# MDR1986VE8 register map
Vendor: Milandr; Series: ARMCM4; File version: 2.0
ARM 32-bit Cortex-M4 Microcontroller based device, CPU clock up to 60MHz, etc.
CPU: CM4 r0p0, little endian, MPU, FPU, 3 interrupt priority bits
Registers are 32-bit, read-write, reset 0x0 unless marked. A register's access mark holds for its fields unless they carry their own. Offsets are from the block's base; lines under a group give offsets from that group; [hi:lo] are bit positions; {n}, {i} and the like mark numbered series; 'fields as' and 'values as' point back to an identical list; <NAME> marks a mode.

## Memory map
0x21000000 MDR_ETH1 size 0x3A — Ethernet Control
0x40000000 MDR_RST_CLOCK size 0x1D0 — CLock Control
0x40001000 MDR_BKP size 0x184 — Backup and RTC Control
0x40006000 MDR_OTP size 0x28 — OTP Memory Control
0x40080000 MDR_PORTA size 0x8C — PORTA
0x40081000 MDR_PORTB size 0x8C — PORTB
0x40082000 MDR_PORTC size 0x8C — PORTC
0x40083000 MDR_PORTD size 0x8C — PORTD
0x40084000 MDR_PORTE size 0x8C — PORTE
0x4008A000 MDR_TIMER1 size 0x90 — TIMER Control
0x4008B000 MDR_TIMER2 size 0x90
0x4008C000 MDR_TIMER3 size 0x90
0x4008D000 MDR_TIMER4 size 0x90
0x40090000 MDR_CAN1 size 0x600 — CAN Control
0x40095000 MDR_SSP1 size 0x28 — Synchronous Serial Port
0x40099000 MDR_UART1 size 0x84 — UART Control
0x4009A000 MDR_UART2 size 0x84
0xE0042000 MDR_DMA size 0x70 — DMA Controler

## MDR_OTP — OTP Memory Control
Base 0x40006000
0x00 KEY — Unlock block register
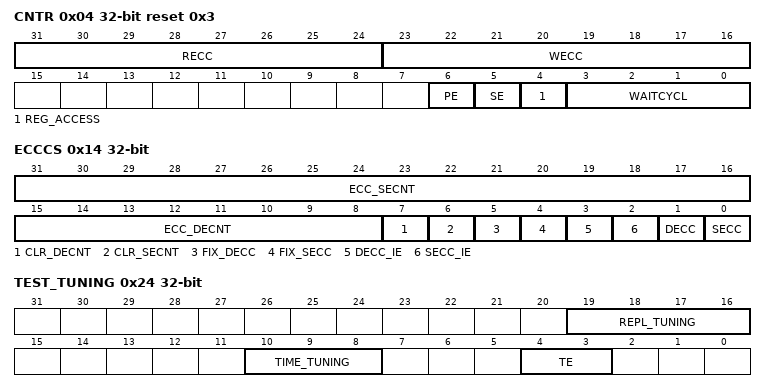
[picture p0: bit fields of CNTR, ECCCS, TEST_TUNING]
0x04 CNTR reset 0x3 — Control register
  [31:24] RECC — ECC after read with RDATA
  [23:16] WECC — ECC for write with WDATA
  [6] PE — OTP Programming enable
    0=Off (Hold data); 1=On (Programming enable)
  [5] SE — OTP Read enable
    0=Off (Hold data); 1=On (Read enable)
  [4] REG_ACCESS — OTP Access Delay
    0=Off (Bus access); 1=On (Access through registers)
  [3:0] WAITCYCL — OTP Access Delay
    0=Forbiden value; 1=20MHz83 (Delay for clock up to 20.83 MHz); 2=41MHz66 (Delay for clock up to 41.66 MHz); 3=62MHz5 (Delay for clock up to 62.5 MHz); 4=83MHz33 (Delay for clock up to 83.33 MHz); 5=100MHz (Delay for clock up to 100 MHz)
0x08 ADR — Access address
0x0C WDATA — Data to write
0x10 RDATA — Read out data
0x14 ECCCS — Control-Status Register
  [31:16] ECC_SECNT — SE Events Counter
  [15:8] ECC_DECNT — DE Events Counter
  [7] CLR_DECNT — Clear DE counter
    0=Inactive (No Action); 1=Clear (Action)
  [6] CLR_SECNT — Clear SE counter
    0=Inactive (No Action); 1=Clear (Action)
  [5] FIX_DECC — Log DE to ECCADR, ECCDATA, ECCECC
    0=Off (Disable); 1=On (Enable)
  [4] FIX_SECC — Log SE to ECCADR, ECCDATA, ECCECC
    0=Off (Disable); 1=On (Enable)
  [3] DECC_IE — DoubleError IRQ Enable
    0=Off (Disable); 1=On (Enable)
  [2] SECC_IE — SingleError IRQ Enable
    0=Off (Disable); 1=On (Enable)
  [1] DECC — DoubleError flag
    0=Off (No Event detected); 1=On (Event detected)
  [0] SECC — SingleError flag
    0=Off (No Event detected); 1=On (Event detected)
0x18 ECCADR — Last error address without correction
0x1C ECCDATA — Last error data without correction
0x20 ECCECC (reset mask 0xFF) — Last error ECC without correction
0x24 TEST_TUNING — Access Memory Tuning register
  [19:16] REPL_TUNING — Bit Hi_Level Read Resistance
    0=Repl_EasyMax (Read Resistance); 1=Repl_Easy1 (Read Resistance); 2=Repl_Norm (Read Resistance); {v}=Repl_Hard{v-2} (Read Resistance) (v=3..14); 15=Repl_HardMax (Read Resistance)
  [10:8] TIME_TUNING — Timeouts to read bit
    0=Time_HardMax (Read Timeout); 1=Time_Hard2 (Read Timeout); 2=Time_Hard1 (Read Timeout); 3=Time_Norm (Read Timeout); 4=Time_Easy1 (Read Timeout); 5=Time_Easy2 (Read Timeout); 6=Time_Easy3 (Read Timeout); 7=Time_EasyMax (Read Timeout)
  [4:3] TE — Select Test Mode
    0=Off (Normal Operation); 1=Test_1 (Test Mode 1); 2=Test_2 (Test Mode 2); 3=Test_3 (Test Mode 3)

## MDR_SSP1 — Synchronous Serial Port
Base 0x40095000
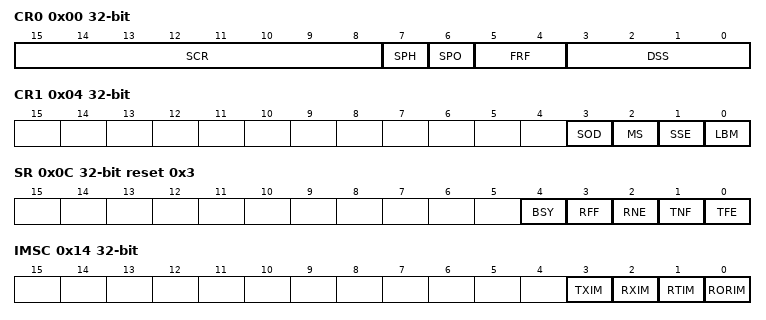
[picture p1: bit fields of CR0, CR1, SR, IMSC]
0x00 CR0 — Control Register 0
  [15:8] SCR — Signal CLock Rate
  [7] SPH — SPI Capture Clock Phase
    0=Leading (Capture data on leading edge); 1=Trailing (Capture data on trailing edge)
  [6] SPO — SPI Clock Polarity
    0=Idle_Low (Idle state is Low); 1=Idle_High (Idle state is High)
  [5:4] FRF — Frame Format
    0=SPI (Motorola SPI protocol); 1=SSI (Texas Instruments SSI protocol); 2=Microwire (National Semiconductor Microwire protocol)
  [3:0] DSS — Data Size Select
    {v}=bits_{v+1} (Word of {v+1} bits) (v=3..15)
0x04 CR1 — Control Register 1
  [3] SOD — Slave mode Output Disable
    0=SlaveTxEna (Slave mode transmit enable); 1=SlaveTxDis (Slave mode transmit disable)
  [2] MS — Master or Slave mode
    0=Master Mode; 1=Slave Mode
  [1] SSE — Synchronous Serial Enable
    0=Off (SSP Disable); 1=On (SSP Enable)
  [0] LBM — Loop Back Mode
    0=Normal operation; 1=LoopBack (TX send to RX test mode)
0x08 DR — FIFO_Rx and FIFO_Tx access
  [15:0] Data — Data value
0x0C SR ro reset 0x3 — Status Register
  [4] BSY — Transfer in progress
    0=Idle (FIFO_RX is Not Full); 1=Busy (Transfering)
  [3] RFF — FIFO_RX is Full
    0=RX_NotFull (FIFO_RX is Not Full); 1=RX_Full (FIFO_RX is Full)
  [2] RNE — FIFO_RX is Not Empty
    0=RX_NotEmpty (FIFO_RX is Empty); 1=RX_Empty (FIFO_RX is Not Empty)
  [1] TNF — FIFO_TX is Not Full
    0=TX_Full (FIFO_TX is Full); 1=TX_NotFull (FIFO_TX is Not Full)
  [0] TFE — FIFO_TX is Empty
    0=TX_NotEmpty (FIFO_TX is Not Empty); 1=TX_Empty (FIFO_TX is Empty)
0x10 CPSR — Clock Prescaller Register
  [7:0] CPSDVSR — Clock Prescaller
0x14 IMSC — IRQ Mask Set-Clear
  [3] TXIM — Enable IQR on FIFO_TX le 4 words
    0=NoEvent (Flag Inactive); 1=TX_HalfEmpty (Flag Active)
  [2] RXIM — Enable IQR on FIFO_RX ge 4 words
    0=NoEvent (Flag Inactive); 1=RX_HalfFull (Flag Active)
  [1] RTIM — Enable IQR on RX timeout for 32bits
    0=NoEvent (Flag Inactive); 1=RX_Timeout (Flag Active)
  [0] RORIM — Enable IRQ on FIFO_RX overrun
    0=NoEvent (Flag Inactive); 1=RX_Overrun (Flag Active)
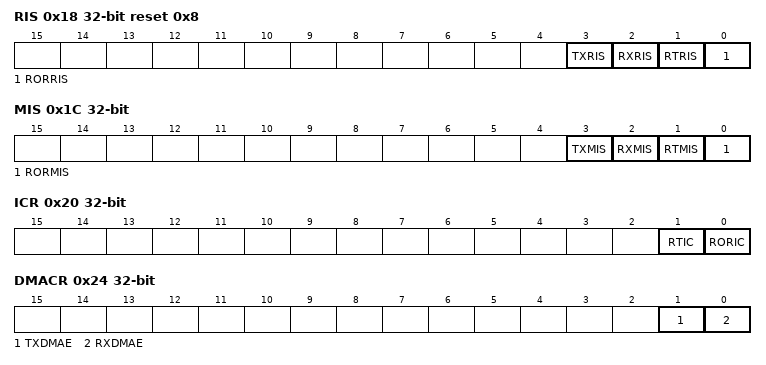
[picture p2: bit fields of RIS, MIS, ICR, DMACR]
0x18 RIS ro reset 0x8 — Raw Interupt Status
  [3] TXRIS — FIFO_TX le words
    0=NoEvent (Flag Inactive); 1=TX_HalfEmpty (Flag Active)
  [2] RXRIS — FIFO_RX gt words
    0=NoEvent (Flag Inactive); 1=RX_HalfFull (Flag Active)
  [1] RTRIS — RX timeout for 32bits
    0=NoEvent (Flag Inactive); 1=RX_Timeout (Flag Active)
  [0] RORRIS — FIFO_RX is overrun
    0=NoEvent (Flag Inactive); 1=RX_Overrun (Flag Active)
0x1C MIS ro — Masked Interupt Status
  [3] TXMIS — FIFO_TX le 4 words
    0=NoEvent (Flag Inactive); 1=TX_HalfEmpty (Flag Active)
  [2] RXMIS — FIFO_RX ge 4 words
    0=NoEvent (Flag Inactive); 1=RX_HalfFull (Flag Active)
  [1] RTMIS — RX timeout for 32bits
    0=NoEvent (Flag Inactive); 1=RX_Timeout (Flag Active)
  [0] RORMIS — FIFO_RX is overrun
    0=NoEvent (Flag Inactive); 1=RX_Overrun (Flag Active)
0x20 ICR wo — Interupt Clear Register
  [1] RTIC — Clear RX timeout flag
    0=Inactive (No action); 1=Clear Flag
  [0] RORIC — Clear FIFO_RX overrun flag
    0=Inactive (No action); 1=Clear Flag
0x24 DMACR — DMA Control Register
  [1] TXDMAE — Enable DMA by FIFO_TX not Full
    0=Disable DMA; 1=Enable DMA
  [0] RXDMAE — Enable DMA by FIFO_RX has data
    0=Disable DMA; 1=Enable DMA
